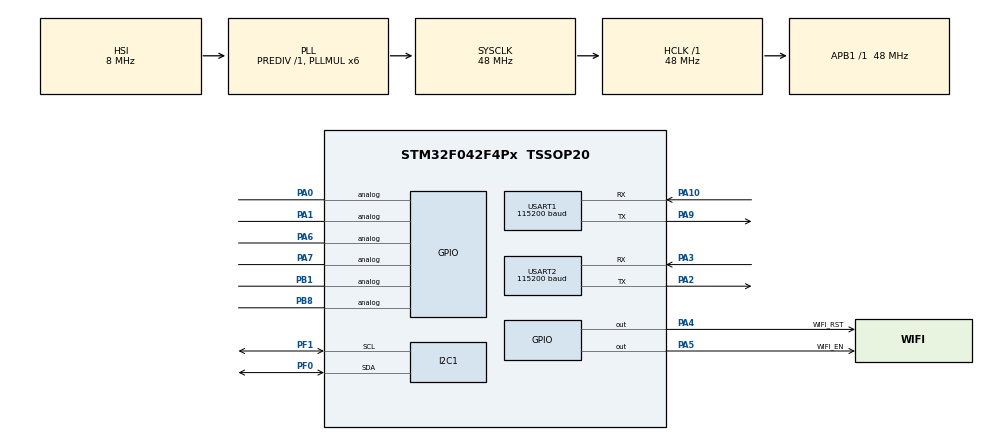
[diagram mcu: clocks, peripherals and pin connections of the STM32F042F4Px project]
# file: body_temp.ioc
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I2C1.Speed=10
I2C1.Timing=0x200009FE
Mcu.Family=STM32F0
Mcu.Name=STM32F042F4Px
Mcu.Package=TSSOP20
NVIC.RTC_IRQn=true\:0\:0\:false\:false\:true\:true\:true
NVIC.USART1_IRQn=true\:0\:0\:false\:false\:true\:true\:true
NVIC.USART2_IRQn=true\:0\:0\:false\:false\:true\:true\:true
PA0.Signal=GPIO_Analog
PA1.Signal=GPIO_Analog
PA10.Mode=Asynchronous
PA10.Signal=USART1_RX
PA13.Mode=Serial_Wire
PA13.Signal=SYS_SWDIO
PA14.Mode=Serial_Wire
PA14.Signal=SYS_SWCLK
PA2.Mode=Asynchronous
PA2.Signal=USART2_TX
PA3.Mode=Asynchronous
PA3.Signal=USART2_RX
PA4.GPIO_Label=WIFI_RST
PA4.Signal=GPIO_Output
PA5.GPIO_Label=WIFI_EN
PA5.Signal=GPIO_Output
PA6.Signal=GPIO_Analog
PA7.Signal=GPIO_Analog
PA9.Mode=Asynchronous
PA9.Signal=USART1_TX
PB1.Signal=GPIO_Analog
PB8.Signal=GPIO_Analog
PF0-OSC_IN.Mode=I2C
PF0-OSC_IN.Signal=I2C1_SDA
PF1-OSC_OUT.Mode=I2C
PF1-OSC_OUT.Signal=I2C1_SCL
ProjectManager.HeapSize=0x200
ProjectManager.StackSize=0x400
ProjectManager.TargetToolchain=MDK-ARM V5
RCC.AHBFreq_Value=48000000
RCC.APB1Freq_Value=48000000
RCC.APB1TimFreq_Value=48000000
RCC.HCLKFreq_Value=48000000
RCC.PLLMUL=RCC_PLL_MUL6
RCC.SYSCLKFreq_VALUE=48000000
RCC.SYSCLKSource=RCC_SYSCLKSOURCE_PLLCLK
RTC.Alarm=RTC_ALARM_A
RTC.Format=RTC_FORMAT_BIN
RTC.Hours=1
RTC.Hours_A=1
RTC.Minutes_A=20
RTC.Seconds_A=0
RTC.SubSeconds_A=0
RTC.SynchPrediv=311
USART1.BaudRate=115200
USART1.VirtualMode=VM_ASYNC
USART2.BaudRate=115200
USART2.VirtualMode-Asynchronous=VM_ASYNC
VP_RTC_VS_RTC_Activate.Mode=RTC_Enabled
VP_RTC_VS_RTC_Alarm_A_Intern.Mode=Alarm A
VP_RTC_VS_RTC_Calendar.Mode=RTC_Calendar
board=custom

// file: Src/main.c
/* USER CODE BEGIN Header */
/**
  ******************************************************************************
  * @file           : main.c
  * @brief          : Main program body
  ******************************************************************************
  * @attention
  *
  * <h2><center>&copy; Copyright (c) 2020 STMicroelectronics.
  * All rights reserved.</center></h2>
  *
  * This software component is licensed by ST under Ultimate Liberty license
  * SLA0044, the "License"; You may not use this file except in compliance with
  * the License. You may obtain a copy of the License at:
  *                             www.st.com/SLA0044
  *
  ******************************************************************************
  */
/* USER CODE END Header */

#include "main.h"
#include "i2c.h"
#include "rtc.h"
#include "usart.h"
#include "gpio.h"

/* USER CODE BEGIN Includes */
//#include "usbd_cdc_if.h"

#include <string.h>
#include "function.h"
#include "Si7021_driver.h"
/* USER CODE END Includes */

void SystemClock_Config(void);

/* USER CODE BEGIN 0 */
//float temp_buf[BUFFER_TEMP_SIZE]={0.0};												//массив для хранения показаний температуры за сутки
/* USER CODE END 0 */

int main(void)
{

  /* MCU Configuration--------------------------------------------------------*/

  /* Reset of all peripherals, Initializes the Flash interface and the Systick. */
  HAL_Init();

  /* Configure the system clock */
  SystemClock_Config();

  /* Initialize all configured peripherals */
  MX_GPIO_Init();
  MX_USART2_UART_Init();
  MX_I2C1_Init();
  MX_USART1_UART_Init();
  MX_RTC_Init();
  /* USER CODE BEGIN 2 */

	USART2->CR1 = USART_CR1_UE;
	NVIC_EnableIRQ(USART2_IRQn); USART2->CR1 |= USART_CR1_TE | USART_CR1_RE | USART_CR1_RXNEIE;        //разрешение прерывания по приёму данных UART2
	WIFI_EN;
  /* USER CODE END 2 */

  /* Infinite loop */
  /* USER CODE BEGIN WHILE */
	HAL_Delay(200);
	debug((uint8_t*)"Start system\r\n",0);

	rst_Si7021();
	//uint16_t wait_send_server=0;
  while (1)
  {
		//debug_uid();
		commands();																											//обработка очереди команд в системном регистре флагов com_flags (16 бит)
		HAL_Delay(100);
    /* USER CODE END WHILE */

  }
}

void SystemClock_Config(void)
{
  RCC_OscInitTypeDef RCC_OscInitStruct = {0};
  RCC_ClkInitTypeDef RCC_ClkInitStruct = {0};
  RCC_PeriphCLKInitTypeDef PeriphClkInit = {0};

  /** Initializes the CPU, AHB and APB busses clocks
  */
  RCC_OscInitStruct.OscillatorType = RCC_OSCILLATORTYPE_HSI|RCC_OSCILLATORTYPE_LSI;
  RCC_OscInitStruct.HSIState = RCC_HSI_ON;
  RCC_OscInitStruct.HSICalibrationValue = RCC_HSICALIBRATION_DEFAULT;
  RCC_OscInitStruct.LSIState = RCC_LSI_ON;
  RCC_OscInitStruct.PLL.PLLState = RCC_PLL_ON;
  RCC_OscInitStruct.PLL.PLLSource = RCC_PLLSOURCE_HSI;
  RCC_OscInitStruct.PLL.PLLMUL = RCC_PLL_MUL6;
  RCC_OscInitStruct.PLL.PREDIV = RCC_PREDIV_DIV1;
  if (HAL_RCC_OscConfig(&RCC_OscInitStruct) != HAL_OK)
  {
    Error_Handler();
  }
  /** Initializes the CPU, AHB and APB busses clocks
  */
  RCC_ClkInitStruct.ClockType = RCC_CLOCKTYPE_HCLK|RCC_CLOCKTYPE_SYSCLK
                              |RCC_CLOCKTYPE_PCLK1;
  RCC_ClkInitStruct.SYSCLKSource = RCC_SYSCLKSOURCE_PLLCLK;
  RCC_ClkInitStruct.AHBCLKDivider = RCC_SYSCLK_DIV1;
  RCC_ClkInitStruct.APB1CLKDivider = RCC_HCLK_DIV1;

  if (HAL_RCC_ClockConfig(&RCC_ClkInitStruct, FLASH_LATENCY_1) != HAL_OK)
  {
    Error_Handler();
  }
  PeriphClkInit.PeriphClockSelection = RCC_PERIPHCLK_USART1|RCC_PERIPHCLK_I2C1
                              |RCC_PERIPHCLK_RTC;
  PeriphClkInit.Usart1ClockSelection = RCC_USART1CLKSOURCE_PCLK1;
  PeriphClkInit.I2c1ClockSelection = RCC_I2C1CLKSOURCE_HSI;
  PeriphClkInit.RTCClockSelection = RCC_RTCCLKSOURCE_LSI;
  if (HAL_RCCEx_PeriphCLKConfig(&PeriphClkInit) != HAL_OK)
  {
    Error_Handler();
  }
}

void Error_Handler(void)
{
}

/************************ (C) COPYRIGHT STMicroelectronics *****END OF FILE****/
